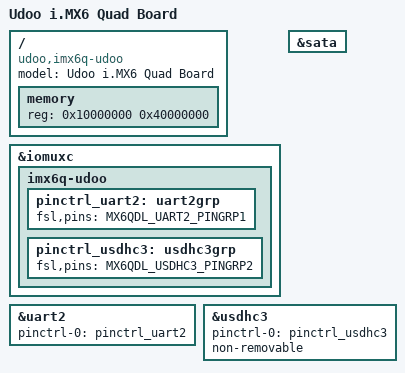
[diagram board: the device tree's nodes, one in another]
/*
 * Copyright 2013 Freescale Semiconductor, Inc.
 *
 * Author: Fabio Estevam <fabio.estevam@freescale.com>
 *
 * This program is free software; you can redistribute it and/or modify
 * it under the terms of the GNU General Public License version 2 as
 * published by the Free Software Foundation.
 *
 */

/dts-v1/;
#include "imx6q.dtsi"

/ {
	model = "Udoo i.MX6 Quad Board";
	compatible = "udoo,imx6q-udoo", "fsl,imx6q";

	memory {
		reg = <0x10000000 0x40000000>;
	};
};

&iomuxc {
	imx6q-udoo {
		pinctrl_uart2: uart2grp {
			fsl,pins = <MX6QDL_UART2_PINGRP1>;
		};

		pinctrl_usdhc3: usdhc3grp {
			fsl,pins = <MX6QDL_USDHC3_PINGRP2>;
		};
	};
};

&sata {
	status = "okay";
};

&uart2 {
	pinctrl-names = "default";
	pinctrl-0 = <&pinctrl_uart2>;
	status = "okay";
};

&usdhc3 {
	pinctrl-names = "default";
	pinctrl-0 = <&pinctrl_usdhc3>;
	non-removable;
	status = "okay";
};
